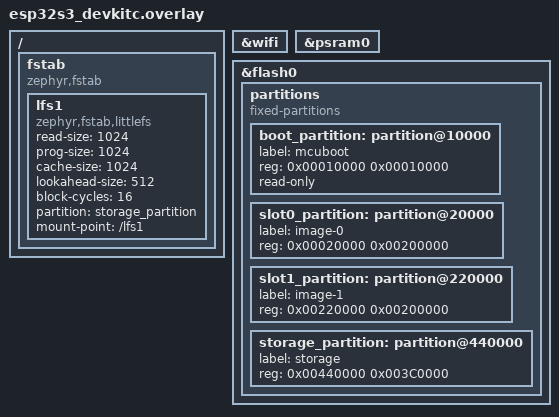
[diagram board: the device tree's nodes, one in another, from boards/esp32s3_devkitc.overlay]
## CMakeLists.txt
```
# SPDX-License-Identifier: Apache-2.0

cmake_minimum_required(VERSION 3.20.0)

find_package(Zephyr REQUIRED HINTS $ENV{ZEPHYR_BASE})
project(fs_shell)

set(MSS_DIR  "${CMAKE_CURRENT_SOURCE_DIR}/../../..")
set(MSS_SRC_DIR "${MSS_DIR}/src")
set(TRUSTCORE_LIB_DIR "${MSS_DIR}/bin_static")

include_directories(
  ${MSS_SRC_DIR}
)

FILE(GLOB app_sources src/*.c)
target_sources(app PRIVATE ${app_sources})

file(GLOB EXTERNAL_LIBS "${TRUSTCORE_LIB_DIR}/*.a")

if("${BOARD}" STREQUAL "native_sim")
  add_definitions("-D__DIGICERT_SAMPLE_NATIVE_SIM__")
elseif ("${BOARD}" STREQUAL "esp32s3_devkitc")
  add_definitions("-D__ENABLE_DIGICERT_ESP32S3__")
endif()

foreach(lib_path ${EXTERNAL_LIBS})
  get_filename_component(lib_name ${lib_path} NAME_WE)
  message(STATUS "Linking library: ${lib_name} => ${lib_path}")

  add_library(${lib_name} STATIC IMPORTED GLOBAL)
  set_target_properties(${lib_name} PROPERTIES IMPORTED_LOCATION ${lib_path})
  target_link_libraries(app PUBLIC ${lib_name})
endforeach()
```

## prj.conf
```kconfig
# Set the name of target binary
CONFIG_KERNEL_BIN_NAME="trustedge"
#CONFIG_DEBUG=y
#CONFIG_SIZE_OPTIMIZATIONS_AGGRESSIVE=y

# the number of bytes in the arena for C library malloc
CONFIG_COMMON_LIBC_MALLOC=y
CONFIG_COMMON_LIBC_MALLOC_ARENA_SIZE=110000

CONFIG_REQUIRES_FULL_LIBC=y

# number of bytes for k_malloc
CONFIG_HEAP_MEM_POOL_SIZE=25000

CONFIG_POSIX_API=y

# for enabling poxis threads
CONFIG_POSIX_THREADS=y # pthread
CONFIG_POSIX_TIMERS=y
CONFIG_THREAD_STACK_INFO=y
CONFIG_DYNAMIC_THREAD=y

CONFIG_DYNAMIC_THREAD_POOL_SIZE=20
CONFIG_DYNAMIC_THREAD_STACK_SIZE=2048
CONFIG_POSIX_THREAD_KEYS_MAX=20
CONFIG_POSIX_THREAD_THREADS_MAX=20
CONFIG_MAX_PTHREAD_MUTEX_COUNT=20
CONFIG_MAX_PTHREAD_COND_COUNT=20

# Enable thread awareness for debugging tools supporting it
CONFIG_DEBUG_THREAD_INFO=y

CONFIG_LOG=y

CONFIG_SHELL=y
CONFIG_SHELL_LOG_LEVEL_INF=y

CONFIG_FILE_SYSTEM=y
CONFIG_FILE_SYSTEM_SHELL=y

CONFIG_FILE_SYSTEM_LITTLEFS=y
CONFIG_FLASH_MAP=y
CONFIG_FLASH=y

# Networking config
CONFIG_NET_SOCKETS_LOG_LEVEL_DBG=n
CONFIG_NET_SOCKETS=y
CONFIG_NETWORKING=y
CONFIG_NET_IPV4=y
CONFIG_NET_IPV6=n
CONFIG_NET_IF_MAX_IPV4_COUNT=2
CONFIG_NET_TCP=y
CONFIG_NET_LOG=y

CONFIG_NET_SHELL=y

# Network address config
CONFIG_NET_CONFIG_SETTINGS=y
CONFIG_NET_CONFIG_NEED_IPV4=y
CONFIG_NET_DHCPV4=y

CONFIG_NET_TCP_LOG_LEVEL_DBG=n

CONFIG_HWINFO=y

CONFIG_MAIN_STACK_SIZE=4096

# Set current time from ntp server
CONFIG_SNTP=y
CONFIG_SNTP_LOG_LEVEL_DBG=n
CONFIG_NET_CONFIG_CLOCK_SNTP_INIT=y
CONFIG_NET_CONFIG_SNTP_INIT_RESYNC=y
CONFIG_NET_CONFIG_SNTP_INIT_SERVER="north-america.pool.ntp.org"
```

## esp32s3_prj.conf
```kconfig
# Set the name of target binary
#CONFIG_KERNEL_BIN_NAME="trustedge"
#CONFIG_DEBUG=y
#CONFIG_SIZE_OPTIMIZATIONS_AGGRESSIVE=y

# the number of bytes in the arena for C library malloc
#CONFIG_COMMON_LIBC_MALLOC=y
CONFIG_COMMON_LIBC_MALLOC_ARENA_SIZE=10000

CONFIG_HEAP_MEM_POOL_SIZE=50000
CONFIG_DYNAMIC_THREAD_STACK_SIZE=4096
CONFIG_MAIN_STACK_SIZE=4000

#CONFIG_ZTEST_STACK_SIZE=4096
CONFIG_SYSTEM_WORKQUEUE_STACK_SIZE=4096
CONFIG_LOG_PROCESS_THREAD_STACK_SIZE=8192
CONFIG_SHELL_STACK_SIZE=8192

CONFIG_LOG_BACKEND_FS=y
CONFIG_LOG_BACKEND_FS_FILE_SIZE=1024000
CONFIG_LOG_BACKEND_FS_FILES_LIMIT=5
CONFIG_LOG_BACKEND_FS_DIR="/lfs1/log"

CONFIG_PRINTK=y
CONFIG_LOG_CMDS=y
CONFIG_INIT_STACKS=y
CONFIG_KERNEL_SHELL=y
CONFIG_THREAD_MONITOR=y
CONFIG_BOOT_BANNER=n
CONFIG_THREAD_NAME=y
CONFIG_DEVICE_SHELL=y
CONFIG_DATE_SHELL=y
CONFIG_THREAD_RUNTIME_STATS=y
CONFIG_THREAD_RUNTIME_STATS_USE_TIMING_FUNCTIONS=y
CONFIG_STATS=y
CONFIG_STATS_SHELL=y
CONFIG_BOOTLOADER_MCUBOOT=y
CONFIG_NET_L2_WIFI_SHELL=y
CONFIG_SHELL=y
CONFIG_SHELL_BACKENDS=y
CONFIG_SHELL_BACKEND_SERIAL=y
CONFIG_FLASH_SHELL=y
CONFIG_CONSOLE=y
CONFIG_UART_CONSOLE=y
CONFIG_SERIAL=y
CONFIG_MULTITHREADING=y
CONFIG_PRINTK=y
CONFIG_LOG=y
CONFIG_LOG_BUFFER_SIZE=8192
CONFIG_ESP32_WIFI_STA_AUTO_DHCPV4=y
CONFIG_WIFI=y
CONFIG_WIFI_ESP32=y
CONFIG_NET_MAX_CONN=15

#CONFIG_NET_CONFIG_MY_IPV4_ADDR="192.168.1.142"
#CONFIG_NET_CONFIG_PEER_IPV4_ADDR="192.168.1.124"
#CONFIG_NET_CONFIG_MY_IPV4_GW="192.168.1.1"
#CONFIG_REQUIRES_FULL_LIBC=y

# number of bytes for k_malloc

#CONFIG_POSIX_API=y

# for enabling poxis threads
#CONFIG_POSIX_THREADS=y # pthread
#CONFIG_POSIX_TIMERS=y
#CONFIG_THREAD_STACK_INFO=y
#CONFIG_DYNAMIC_THREAD=y

#CONFIG_DYNAMIC_THREAD_POOL_SIZE=20
#CONFIG_POSIX_THREAD_KEYS_MAX=20
#CONFIG_POSIX_THREAD_THREADS_MAX=20
#CONFIG_MAX_PTHREAD_MUTEX_COUNT=20
#CONFIG_MAX_PTHREAD_COND_COUNT=20

# Enable thread awareness for debugging tools supporting it
#CONFIG_DEBUG_THREAD_INFO=y

#CONFIG_LOG=y

#CONFIG_SHELL=y
#CONFIG_SHELL_LOG_LEVEL_INF=y

#CONFIG_FILE_SYSTEM=y
#CONFIG_FILE_SYSTEM_SHELL=y

#CONFIG_FILE_SYSTEM_LITTLEFS=y
#CONFIG_FLASH_MAP=y
#CONFIG_FLASH=y

# Networking config
#CONFIG_NET_SOCKETS_LOG_LEVEL_DBG=n
#CONFIG_NET_SOCKETS=y
#CONFIG_NETWORKING=y
#CONFIG_NET_IPV4=y
#CONFIG_NET_DHCPV4=y
#CONFIG_NET_IPV6=n
#CONFIG_NET_IF_MAX_IPV4_COUNT=2
#CONFIG_NET_TCP=y
#CONFIG_NET_LOG=y

#CONFIG_NET_SHELL=y

#CONFIG_NET_CONFIG_SETTINGS=y
#CONFIG_NET_CONFIG_NEED_IPV4=y

#CONFIG_NET_MAX_CONN=10

#CONFIG_ZVFS_POLL_MAX=10
#CONFIG_ZVFS_OPEN_MAX=10
# Enable the DNS resolver
#CONFIG_DNS_RESOLVER=y
# Enable additional buffers
#CONFIG_DNS_RESOLVER_ADDITIONAL_BUF_CTR=5
# Enable additional queries
#CONFIG_DNS_RESOLVER_ADDITIONAL_QUERIES=2
# Enable mDNS support
#CONFIG_MDNS_RESOLVER=y
# Enable LLMNR support
#CONFIG_LLMNR_RESOLVER=n

#CONFIG_DNS_RESOLVER_MAX_SERVERS=2
#CONFIG_DNS_SERVER_IP_ADDRESSES=y
#CONFIG_DNS_NUM_CONCUR_QUERIES=5

#CONFIG_DNS_SERVER1="8.8.8.8:53"
#CONFIG_DNS_SERVER2="1.1.1.1:53"

#CONFIG_NET_PKT_RX_COUNT=12
#CONFIG_NET_PKT_TX_COUNT=12
#CONFIG_NET_BUF_RX_COUNT=64
#CONFIG_NET_BUF_TX_COUNT=64

#CONFIG_NET_TCP_LOG_LEVEL_DBG=n

#CONFIG_HWINFO=y


# Set current time from ntp server
#CONFIG_SNTP=y
#CONFIG_SNTP_LOG_LEVEL_DBG=n
#CONFIG_NET_CONFIG_CLOCK_SNTP_INIT=y
#CONFIG_NET_CONFIG_SNTP_INIT_RESYNC=y
#CONFIG_NET_CONFIG_SNTP_INIT_SERVER="north-america.pool.ntp.org"
```

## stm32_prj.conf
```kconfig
# Set the name of target binary
#CONFIG_KERNEL_BIN_NAME="trustedge"
#CONFIG_DEBUG=y
#CONFIG_SIZE_OPTIMIZATIONS_AGGRESSIVE=y

# the number of bytes in the arena for C library malloc
#CONFIG_COMMON_LIBC_MALLOC=y
CONFIG_COMMON_LIBC_MALLOC_ARENA_SIZE=102000

CONFIG_HEAP_MEM_POOL_SIZE=17000
CONFIG_DYNAMIC_THREAD_STACK_SIZE=14000
CONFIG_MAIN_STACK_SIZE=50000

#CONFIG_ZTEST_STACK_SIZE=4096
CONFIG_SYSTEM_WORKQUEUE_STACK_SIZE=4096
CONFIG_LOG_PROCESS_THREAD_STACK_SIZE=4096
CONFIG_SHELL_STACK_SIZE=4096

CONFIG_LOG_BACKEND_FS=y
CONFIG_LOG_BACKEND_FS_FILE_SIZE=1024000
CONFIG_LOG_BACKEND_FS_FILES_LIMIT=5
CONFIG_LOG_BACKEND_FS_DIR="/lfs1/log"

CONFIG_PRINTK=y
CONFIG_LOG_CMDS=y
CONFIG_INIT_STACKS=y
CONFIG_KERNEL_SHELL=y
CONFIG_THREAD_MONITOR=y
CONFIG_BOOT_BANNER=n
CONFIG_THREAD_NAME=y
CONFIG_DEVICE_SHELL=y
CONFIG_DATE_SHELL=y
CONFIG_THREAD_RUNTIME_STATS=y
CONFIG_THREAD_RUNTIME_STATS_USE_TIMING_FUNCTIONS=y
CONFIG_STATS=y
CONFIG_STATS_SHELL=y

#CONFIG_NET_CONFIG_MY_IPV4_ADDR="192.168.1.142"
#CONFIG_NET_CONFIG_PEER_IPV4_ADDR="192.168.1.124"
#CONFIG_NET_CONFIG_MY_IPV4_GW="192.168.1.1"
#CONFIG_REQUIRES_FULL_LIBC=y

# number of bytes for k_malloc

#CONFIG_POSIX_API=y

# for enabling poxis threads
#CONFIG_POSIX_THREADS=y # pthread
#CONFIG_POSIX_TIMERS=y
#CONFIG_THREAD_STACK_INFO=y
#CONFIG_DYNAMIC_THREAD=y

#CONFIG_DYNAMIC_THREAD_POOL_SIZE=20
#CONFIG_POSIX_THREAD_KEYS_MAX=20
#CONFIG_POSIX_THREAD_THREADS_MAX=20
#CONFIG_MAX_PTHREAD_MUTEX_COUNT=20
#CONFIG_MAX_PTHREAD_COND_COUNT=20

# Enable thread awareness for debugging tools supporting it
#CONFIG_DEBUG_THREAD_INFO=y

#CONFIG_LOG=y

#CONFIG_SHELL=y
#CONFIG_SHELL_LOG_LEVEL_INF=y

#CONFIG_FILE_SYSTEM=y
#CONFIG_FILE_SYSTEM_SHELL=y

#CONFIG_FILE_SYSTEM_LITTLEFS=y
#CONFIG_FLASH_MAP=y
#CONFIG_FLASH=y

# Networking config
#CONFIG_NET_SOCKETS_LOG_LEVEL_DBG=n
#CONFIG_NET_SOCKETS=y
#CONFIG_NETWORKING=y
#CONFIG_NET_IPV4=y
#CONFIG_NET_DHCPV4=y
#CONFIG_NET_IPV6=n
#CONFIG_NET_IF_MAX_IPV4_COUNT=2
#CONFIG_NET_TCP=y
#CONFIG_NET_LOG=y

#CONFIG_NET_SHELL=y

#CONFIG_NET_CONFIG_SETTINGS=y
#CONFIG_NET_CONFIG_NEED_IPV4=y

#CONFIG_NET_MAX_CONN=10

#CONFIG_ZVFS_POLL_MAX=10
#CONFIG_ZVFS_OPEN_MAX=10
# Enable the DNS resolver
#CONFIG_DNS_RESOLVER=y
# Enable additional buffers
#CONFIG_DNS_RESOLVER_ADDITIONAL_BUF_CTR=5
# Enable additional queries
#CONFIG_DNS_RESOLVER_ADDITIONAL_QUERIES=2
# Enable mDNS support
#CONFIG_MDNS_RESOLVER=y
# Enable LLMNR support
#CONFIG_LLMNR_RESOLVER=n

#CONFIG_DNS_RESOLVER_MAX_SERVERS=2
#CONFIG_DNS_SERVER_IP_ADDRESSES=y
#CONFIG_DNS_NUM_CONCUR_QUERIES=5

#CONFIG_DNS_SERVER1="8.8.8.8:53"
#CONFIG_DNS_SERVER2="1.1.1.1:53"

#CONFIG_NET_PKT_RX_COUNT=12
#CONFIG_NET_PKT_TX_COUNT=12
#CONFIG_NET_BUF_RX_COUNT=64
#CONFIG_NET_BUF_TX_COUNT=64

#CONFIG_NET_TCP_LOG_LEVEL_DBG=n

#CONFIG_HWINFO=y


# Set current time from ntp server
#CONFIG_SNTP=y
#CONFIG_SNTP_LOG_LEVEL_DBG=n
#CONFIG_NET_CONFIG_CLOCK_SNTP_INIT=y
#CONFIG_NET_CONFIG_SNTP_INIT_RESYNC=y
#CONFIG_NET_CONFIG_SNTP_INIT_SERVER="north-america.pool.ntp.org"
```

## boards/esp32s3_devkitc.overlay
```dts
/ {
    fstab {
        compatible = "zephyr,fstab";
        lfs1: lfs1 {
            compatible = "zephyr,fstab,littlefs";
            read-size = <1024>;
            prog-size = <1024>;
            cache-size = <1024>;
            lookahead-size = <512>;
            block-cycles = <16>;
            partition = <&storage_partition>;
            mount-point = "/lfs1";
        };
    };
};

&wifi {
    status = "okay";
};

&psram0 {
    status = "okay";
};

&flash0 {
    /delete-node/ partitions;
    partitions {
        compatible = "fixed-partitions";
        #address-cells = <1>;
        #size-cells = <1>;

        boot_partition: partition@10000 {
            label = "mcuboot";
            reg = <0x00010000 0x00010000>; /* 64KB */
            read-only;
        };

        slot0_partition: partition@20000 {
            label = "image-0";
            reg = <0x00020000 0x00200000>; /* 2MB */
        };

        slot1_partition: partition@220000 {
            label = "image-1";
            reg = <0x00220000 0x00200000>; /* 2MB */
        };

        storage_partition: partition@440000 {
            label = "storage";
            reg = <0x00440000 0x003C0000>; /* 3.75MB */
        };
    };
};
```

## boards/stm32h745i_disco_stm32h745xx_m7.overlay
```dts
/*
 * Copyright (c) 2023 S&C Electric Company <www.sandc.com>
 * Copyright (c) 2024 STMicroelectronics
 *
 * SPDX-License-Identifier: Apache-2.0
 */

/ {
	fstab {
		compatible = "zephyr,fstab";
		lfs1: lfs1 {
			compatible = "zephyr,fstab,littlefs";
			read-size = <32>;
			prog-size = <32>;
			cache-size = <256>;
			lookahead-size = <64>;
			block-cycles = <512>;
			partition = <&fs_partition>;
			mount-point = "/lfs1";
		};
	};
};
&flash0 {
	partitions {
		compatible = "fixed-partitions";
		#address-cells = <1>;
		#size-cells = <1>;

		boot_partition: partition@0 {
			label = "mcuboot";
			reg = <0x00000000 0x00010000>; /* 64k */
		};

		slot0_partition: partition@10000 {
			label = "image-0";
			reg = <0x00010000 0x0018DF30>;
		};

		/* total flash memory        -> 001FFC00 */
		/* remaining flash available -> 00061CD0 */
		/* use remaining flash for the file system */
		storage2_partition: partition@19DF30 {
			label = "storage2";
			reg = <0x0019DF30 0x00061CD0>;
		};
	};
};

&mt25ql512ab1 {
	partitions {
		fs_partition: partition@0 {
			label = "fs";
			reg = <0x0 DT_SIZE_M(64)>;
		};
	};
};
```

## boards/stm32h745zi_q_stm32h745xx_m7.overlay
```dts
/*
 * Copyright (c) 2023 S&C Electric Company <www.sandc.com>
 * Copyright (c) 2024 STMicroelectronics
 *
 * SPDX-License-Identifier: Apache-2.0
 */

/ {
	fstab {
		compatible = "zephyr,fstab";
		lfs1: lfs1 {
			compatible = "zephyr,fstab,littlefs";
			read-size = <32>;
			prog-size = <32>;
			cache-size = <256>;
			lookahead-size = <64>;
			block-cycles = <512>;
			partition = <&fs_partition>;
			mount-point = "/lfs1";
		};
	};
};
&flash0 {
	partitions {
		compatible = "fixed-partitions";
		#address-cells = <1>;
		#size-cells = <1>;

		boot_partition: partition@0 {
			label = "mcuboot";
			reg = <0x00000000 0x00010000>; /* 64k */
		};

		slot0_partition: partition@10000 {
			label = "image-0";
			reg = <0x00010000 0x0018DF30>;
		};

		/* total flash memory        -> 001FFC00 */
		/* remaining flash available -> 00061CD0 */
		/* use remaining flash for the file system */
		fs_partition: partition@19DF30 {
			label = "fs";
			reg = <0x0019DF30 0x00061CD0>;
		};
	};
};
```

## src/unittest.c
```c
/*
*  unittest.c
*
*   unit test support
*
* Copyright Mocana Corp 2006. All Rights Reserved.
* Proprietary and Confidential Material.
*
*/

#include "unittest.h"
#include "../src/common/mtypes.h"
    
#if (defined(WIN32) && defined(_DEBUG))
#include <CrtDbg.h>
#endif

#include <assert.h>
#if defined( __RTOS_WIN32__) || defined( __RTOS_LINUX__) || \
    defined(__RTOS_CYGWIN__) || defined( __RTOS_SOLARIS__) || \
    defined(__RTOS_VXWORKS__) || defined( __RTOS_OSX__) || \
    defined(__RTOS_OPENBSD__) || defined( __RTOS_FREEBSD__) || \
    defined(__RTOS_IRIX__) || defined( __RTOS_DUMMY__ ) || \
    defined(__RTOS_SYMBIAN32__)  || defined(__RTOS_WINCE__) || \
    defined(__RTOS_QNX__)
#include <stdio.h>
#define PRINTF      printf
#else
/* OSes with no printf go here and need to define equivalent functionality*/
/* need to support only %s and %d format strings with no extensions */
#endif
#define PRINTF      printf

/************************************
// Test execution debug-io support.
*************************************/
#define UT_DBG_COMM_HIGH_V   1 /* 0 = OFF 1 = ON */


/*-------------------------------------------------------------------------*/
#ifdef __UNITTEST_REMOTE_SUPPORT__


#define UT_DEBUG_PRINT(t,b,c) ut_debug_print(__FILE__, __LINE__, t, b, c)
static void ut_debug_print(const char* pfile, int iline, int printthis, char *str1, char *str2)
{
    char *pNull = "null";
    if (printthis == 0)
        return;
    if (!str1) str1 = pNull;
    if (!str2) str2 = pNull;
    printf("%s : %d : %s%s\n",pfile,iline,str1,str2);
    
}

#define MAX_DEBUGMSG_SIZE (4*1024)
char debugmsg_spot[MAX_DEBUGMSG_SIZE];
#endif /* __UNITTEST_REMOTE_SUPPORT__ */

int remote_target_socket = 0;	/* Needed by tests to determine if the peer IP address should be used of if localhost is acceptable */

int unittest_intEQ(const char* file, int line, const char* test, 
                int hint, int result, int expected)
{
#ifndef __UNITTEST_REMOTE_SUPPORT__

    if ( result != expected)
    {
        PRINTF("%s:%d:Test %s (%d) (%08x) result = %d, expected = %d\n", 
            file, line, test, hint, hint, result, expected);
        return 1;
    }
    return 0;
#else
    if ( result != expected)
    {
        sprintf(debugmsg_spot,"%s:%d:Test %s (%d) (%08x) result = %d, expected = %d\n",
            file, line, test, hint, hint, result, expected);
        unittest_write(debugmsg_spot);
        return 1;
    }
    return 0;
#endif
}


/*-------------------------------------------------------------------------*/

int unittest_intNE(const char* file, int line, const char* test, 
                int hint, int result, int unExpected)
{
#ifndef __UNITTEST_REMOTE_SUPPORT__
    if ( result == unExpected)
    {
        PRINTF("%s:%d:Test %s (%d)(%08x) result = %d, expected != %d\n",
            file, line, test, hint, hint, result, unExpected);
        return 1;
    }
    return 0;
#else
    if ( result == unExpected)
    {
        sprintf(debugmsg_spot,"%s:%d:Test %s (%d)(%08x) result = %d, expected != %d\n",
            file, line, test, hint, hint, result, unExpected);
        unittest_write(debugmsg_spot);
        return 1;
    }
    return 0;
#endif

}


/*-------------------------------------------------------------------------*/

int unittest_intGE( const char* file, int line, const char* testExpr, 
            int hint, int result, int expected)
{
#ifndef __UNITTEST_REMOTE_SUPPORT__
   if ( result < expected)
    {
        PRINTF("%s:%d:Test %s (%d)(%08x) result = %d, expected >= %d\n", 
            file, line, testExpr, hint, hint, result, expected);
        return 1;
    }
    return 0;
#else
    if ( result < expected)
     {
        sprintf(debugmsg_spot,"%s:%d:Test %s (%d)(%08x) result = %d, expected >= %d\n",
             file, line, testExpr, hint, hint, result, expected);
        unittest_write(debugmsg_spot);
         return 1;
     }
     return 0;
#endif
}


/*-------------------------------------------------------------------------*/

void unittest_write(const char* msg)
{
#ifndef __UNITTEST_REMOTE_SUPPORT__
    PRINTF("%s",msg);
#else
    if (remote_target_socket == 0)
    {
    	/* Host side. */
        PRINTF("%s",msg);
    }
    else
    {
    	/* Target side. */
        ut_write_output_cmd_tgt(remote_target_socket, msg);
    }
#endif
}


/*-------------------------------------------------------------------------*/

char* addhexChar( char* out, const unsigned char c)
{
    int n = (c >> 4) & 0x0F;
    *out++ = (char) ( (n < 0xA) ? '0' + n : 'A' + n - 0x0A);
    n = c & 0xF;
    *out++ =  (char) ( (n < 0xA) ? '0' + n : 'A' + n - 0x0A);
    return out;
}

/*-------------------------------------------------------------------------*/

void unittest_write_buffer( const unsigned char* buff, int buffLen)
{
    char line[82];
    line[80] = '\n';
    line[81] = 0;
    /* 6 groups of 8 hex + space = 54 +
       1 group of 24 chars = 24 -> 78 chars */

    while (buffLen)
    {
        char* out = line;
        int i, maxChars = ( buffLen > 24) ? 24 : buffLen;

        out = line;
        for (i = 0; i < maxChars; ++i)
        {
            out = addhexChar(out, buff[i]);
            if (i % 4 == 3)
            {
                *out++ = ' ';
            }
        }
        while (out != line +54)
        {
            *out++ = ' ';
        }

        for (i = 0; i < maxChars; ++i)
        {
            char c = buff[i];
            *out++ = (c >= 0x20 && c <= 0x7E) ? c : '.';
        }
        while (out != line + 80)
        {
            *out++ = ' ';
        }

        unittest_write(line);

        buff += maxChars;
        buffLen -= maxChars;
        
    }
}


/*-------------------------------------------------------------------------*/

int run_test( const char* testFunName, const char* fileName,
             TestFun testFun, int* pass)
{
    int retVal;

    
#if (defined(WIN32) && defined(_DEBUG))
    _CrtMemState memState;
    /* Get current flag */
    int tmpFlag = _CrtSetDbgFlag( _CRTDBG_REPORT_FLAG );
    /* Turn on extensive checks */
    tmpFlag |= (_CRTDBG_CHECK_ALWAYS_DF | _CRTDBG_LEAK_CHECK_DF);

    /* Set flag to the new value */
    _CrtSetDbgFlag( tmpFlag );
   _CrtSetReportMode( _CRT_WARN, _CRTDBG_MODE_DEBUG );
   _CrtSetReportMode( _CRT_ERROR, _CRTDBG_MODE_DEBUG );
   _CrtSetReportMode( _CRT_ASSERT, _CRTDBG_MODE_DEBUG );

   _CrtMemCheckpoint( &memState);

#endif
    
    PRINTF("Running test %s in file %s\n", testFunName, fileName);
#if 0 //ndef __RTOS_QNX__
    fflush(stdout);
#endif
    retVal = testFun();
#if (defined(WIN32) && defined(_DEBUG))
    if (!_CrtCheckMemory()) ++retVal;
    _CrtMemDumpAllObjectsSince(&memState);
#endif
    if ( 0==retVal)
    {
        PRINTF("%s: Pass\n\n", testFunName);
        ++(*pass);
    }
    else
    {
        PRINTF("%s: Fail: %d error(s)\n\n", testFunName, retVal);
    }
#if 0 //ndef __RTOS_QNX__
    fflush(stdout);
#endif

    return retVal;
}


/*-------------------------------------------------------------------------*/

void report( int total, int pass)
{
    PRINTF(  "\nPass:        %d", pass);
    PRINTF(  "\nFail:        %d", total - pass);
    PRINTF(  "\nTotal tests: %d\n", total);
}


/*-------------------------------------------------------------------------*/

int run_test_by_name( const char* name, TestDescriptor* tests, 
                      int num_tests, int* pass, int* total_tests)
{
    int retVal = 0;
    int i, j, name_len;
    const char* p;

    name_len = 0;
    p = name;

    while (*p) { ++name_len; ++p; }
    if (name_len)
    {
        for (i = 0; i < num_tests; ++i)
        {
            const char* testName;

            testName = tests[i].testName;

            for (j = 0; j < name_len; ++j)
            {
                if (testName[j] != name[j])
                {
                    break;
                }
            }
            if ( name_len == j) /* match */
            {
                (*total_tests)++;
                retVal += run_test(tests[i].testName, tests[i].fileName,
                                   tests[i].testFun, pass);
            }
        }
    }
    return retVal;
}


/*-------------------------------------------------------------------------*/

int list_test_names( TestDescriptor* tests, int num_tests)
{
    int i;

    PRINTF("Available tests:\n\n");
    for (i = 0; i < num_tests; ++i)
    {
        PRINTF("%s",tests[i].testName);
        PRINTF("\n");
    }

    return 0;
}


/*-------------------------------------------------------------------------*/

int run_test_by_names( const char* names[], int num_names, 
                       TestDescriptor* tests, int num_tests, 
                       int* pass, int* total_tests)
{
    int retVal = 0;
    int i;
    
    if (1 == num_names)
    {
        const char* option = names[0];

        if ('-' == option[0]  && 'h' == option[1]  && 0 == option[2] )
        {
            list_test_names(tests, num_tests);
            return 0;
        } 
    }

    for (i = 0; i < num_names; ++i)
    {
        retVal += run_test_by_name( names[i], tests, num_tests, pass, 
                                    total_tests);
    }
    return retVal;
}


#if 0
/* Disable until testmonkey infrastructure could be fixed to handle option
  flags
*/
#include "../src/common/moptions.h"
#include "../src/crypto/hw_accel.h"
#if defined(__ENABLE_HARDWARE_ACCEL_ASYNC_CRYPTO__)
static int utest_hwAccelCtx  = 0;
static int hwAccelRefCount = 0;

int
UNITTEST_getHwAccelChannel(void)
{
    if (0 == utest_hwAccelCtx) {
        HARDWARE_ACCEL_OPEN_CHANNEL(9, &utest_hwAccelCtx);
    }
exit:
    assert(utest_hwAccelCtx != 0);
    return utest_hwAccelCtx;
}

void
UNITTEST_releaseHwAccelChannel(int hwAccelCtx)
{
}
#endif
#endif

#ifdef __UNITTEST_REMOTE_SUPPORT__

/*********************************
 Real remote support.
************************************/
int connect_test_target_h(const char *tgtname, const char *execname,
						  int argc, char* argv[], int timeoutsecs, int *pconnfd)
{
	int rc = 0;
	UT_DEBUG_PRINT(UT_DBG_COMM_HIGH_V,"connect_test_target_h: target name=",tgtname);

    *pconnfd = 0;

    remote_target_socket = 0; /* Host side doesn't use one. */

	UT_DEBUG_PRINT(UT_DBG_COMM_HIGH_V,"connect_test_target_h: "," Load test target.");
	rc = ut_load_test_target_h(tgtname, execname, argc, argv, timeoutsecs);  /* May exec on localhost, may be a nop. */

	if (rc == 0)
	{
		UT_DEBUG_PRINT(UT_DBG_COMM_HIGH_V,"connect_test_target_h: "," Connect test target.");
		rc = ut_connect_test_target_h(tgtname, execname, argc, argv, timeoutsecs, pconnfd); /* Connect via socket. */
	}

	if (rc == 0)
	{
		UT_DEBUG_PRINT(UT_DBG_COMM_HIGH_V,"connect_test_target_h: "," Do Startup cmd.");
		rc = ut_startup_cmd_h(*pconnfd);
	}

	UT_DEBUG_PRINT(UT_DBG_COMM_HIGH_V,"connect_test_target_h"," done.");
	return rc;
}

int stop_test_target_h(int *pconnfd, int timeoutsecs)
{
	int rc = -1;
	UT_DEBUG_PRINT(UT_DBG_COMM_HIGH_V,"stop_test_target_h"," ...");
    if (*pconnfd != 0)
    {
    	UT_DEBUG_PRINT(UT_DBG_COMM_HIGH_V,"stop_test_target_h"," Sending shutdown cmd.");
    	rc = ut_shutdown_cmd_h(*pconnfd, timeoutsecs); /* Send Shutdown cmd and wait for ACK. */

    	rc = ut_disconnect_test_target_h(pconnfd); /* Closes socket. */
    }

	UT_DEBUG_PRINT(UT_DBG_COMM_HIGH_V,"stop_test_target_h"," done.");
	return rc;
}

int run_test_h( int connfd, const char* testFunName, const char* fileName,
             TestFun testFun, int* pass)
{
	int rc = -1;
	int retVal = 0;

	UT_DEBUG_PRINT(UT_DBG_COMM_HIGH_V,"run_test_h"," ...");
    if (connfd != 0)
    {
	    PRINTF("Remotely Running test %s in file %s\n", testFunName, fileName);
    	UT_DEBUG_PRINT(UT_DBG_COMM_HIGH_V,"run_test_h"," Sending run_test cmd.");
    	rc = ut_runtest_cmd_h(connfd, testFunName, fileName, &retVal); /* Send RUNTEST cmd, and wait until _FINISHED received.*/
    }

    if ((0==retVal) && (0==rc))
    {
        PRINTF("%s: Pass\n\n", testFunName);
        ++(*pass);
    }
    else
    {
    	if (rc != 0)
    	{
    		retVal = rc; /* This is to catch comm errors.*/
    	}
        PRINTF("%s: Fail: %d error(s)\n\n", testFunName, retVal);
    }

	UT_DEBUG_PRINT(UT_DBG_COMM_HIGH_V,"run_test_h"," done.");
  	return retVal;

}

int run_test_by_name_h( int connfd, const char* name, TestDescriptor* tests,
                      int num_tests, int* pass)
{
	int index = -1;
	int retVal = 0;
	UT_DEBUG_PRINT(UT_DBG_COMM_HIGH_V,"run_test_by_name_h"," ...");

	index = ut_testindexfromstr(tests, num_tests, name);
	if (index >= 0)
	{
		retVal += run_test_h(connfd, tests[index].testName, tests[index].fileName,
	                         tests[index].testFun, pass);
	}
	else
	{
        PRINTF("%s: Fail: Test not found.\n", name);
	}

	UT_DEBUG_PRINT(UT_DBG_COMM_HIGH_V,"run_test_by_name_h"," done.");
  	return 0;
}

int run_test_by_names_h( int connfd, const char* names[], int num_names,
                       TestDescriptor* tests,
                       int num_tests, int* pass)
{
    int retVal = 0;
    int i;

	UT_DEBUG_PRINT(UT_DBG_COMM_HIGH_V,"run_test_by_names_h"," ...");
    if (1 == num_names)
    {
        const char* option = names[0];

        if ('-' == option[0]  && 'h' == option[1]  && 0 == option[2] )
        {
            list_test_names(tests, num_tests);
            return 0;
        }
    }

    for (i = 0; i < num_names; ++i)
    {
        retVal += run_test_by_name_h(connfd, names[i], tests, num_tests, pass);
    }

	UT_DEBUG_PRINT(UT_DBG_COMM_HIGH_V,"run_test_by_names_h"," done.");
    return retVal;

}


int initcomm_tgt( struct sockaddr *phostip, int *pconnfd)
{
	int rc;

	UT_DEBUG_PRINT(UT_DBG_COMM_HIGH_V,"initcomm_tgt"," ...");
	UT_DEBUG_PRINT(UT_DBG_COMM_HIGH_V,"initcomm_tgt"," Accept incoming connect.");

	remote_target_socket = 0; /* Target side I/O needs this. But default to Zero... */

    rc = ut_initcomm_tgt(phostip, pconnfd);  /* Listen for incoming connections, and accept, returning connected socket. */
    if (rc == 0)
    {
    	remote_target_socket = *pconnfd; /* Target side I/O needs this.*/

    	UT_DEBUG_PRINT(UT_DBG_COMM_HIGH_V,"initcomm_tgt"," Wait for startup cmd.");
    	rc = ut_waitfor_startup_cmd_tgt(*pconnfd);
    }

	UT_DEBUG_PRINT(UT_DBG_COMM_HIGH_V,"initcomm_tgt"," done.");
	return rc;
}

int proc_runtest_cmds_tgt( struct sockaddr *phostip, int connfd, TestDescriptor* tests, int num_tests)
{
	int rc;
	UT_DEBUG_PRINT(UT_DBG_COMM_HIGH_V,"proc_runtest_cmds_tgt"," ...");
	UT_DEBUG_PRINT(UT_DBG_COMM_HIGH_V,"proc_runtest_cmds_tgt"," Wait for runtest cmds.");
	rc = ut_waitfor_runtest_cmd_tgt(connfd, tests, num_tests);
	UT_DEBUG_PRINT(UT_DBG_COMM_HIGH_V,"proc_runtest_cmds_tgt"," done.");
    return rc;
}

int stopcomm_tgt( int *pconnfd, int statusin)
{
	int rc;
	UT_DEBUG_PRINT(UT_DBG_COMM_HIGH_V,"stopcomm_tgt"," ...");

	rc = ut_stopcomm_tgt(pconnfd, statusin);

    remote_target_socket = 0; /* Target side I/O needs this. But default to Zero... */

	UT_DEBUG_PRINT(UT_DBG_COMM_HIGH_V,"stopcomm_tgt"," done.");
	return rc;
}

#endif  /*  __UNITTEST_REMOTE_SUPPORT__ */

#if defined(__ENABLE_DIGICERT_UNITTEST__)

#include <fcntl.h>
#include <unistd.h>
#include <string.h>
#include <stdio.h>

char *gpOutFile[256];
int gOutFD;
int stdoutFD;

void redirectOutput(char *pFile)
{
    fflush(NULL);
    memcpy(gpOutFile, pFile, strlen(pFile));
    gpOutFile[strlen(pFile)] = '\0';
    stdoutFD = dup(1);
    gOutFD = open(pFile, O_CREAT|O_WRONLY|O_TRUNC, 0666);
    dup2(gOutFD, 1);
}

void restoreOutput()
{
    fflush(NULL);
    dup2(stdoutFD, 1);
    close(stdoutFD);
}

#endif /* __ENABLE_DIGICERT_UNITTEST__ */
```

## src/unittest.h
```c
/*
*  unittest.h
*
*   unit test support
*
* Copyright Mocana Corp 2006. All Rights Reserved.
* Proprietary and Confidential Material.
*
*/


#ifndef __UNITTEST_HEADER__
#define __UNITTEST_HEADER__

#ifndef __MOC_LINE__
#define __MOC_LINE__ __LINE__
#endif

#if defined( __UNITTEST_REMOTE_SUPPORT__)
#if defined( __RTOS_WIN32__) || defined( __RTOS_LINUX__) || \
    defined(__RTOS_CYGWIN__) || defined( __RTOS_SOLARIS__) || \
    defined(__RTOS_VXWORKS__) || defined( __RTOS_OSX__) || \
    defined(__RTOS_OPENBSD__) || defined( __RTOS_FREEBSD__) || \
    defined(__RTOS_IRIX__) || defined( __RTOS_DUMMY__ ) || \
    defined(__RTOS_SYMBIAN32__)  || defined(__RTOS_WINCE__)
#include <sys/types.h>
#include <sys/socket.h>
#endif
#endif /* __UNITTEST_REMOTE_SUPPORT__ */

extern int remote_target_socket;    /* Needed by tests to determine if the peer IP address should be used of if localhost is acceptable */

/* prototypes */
typedef int (*TestFun)();

int unittest_intEQ(const char* file, int line, const char* testExpr, 
            int hint, int result, int expected);
int unittest_intGE( const char* file, int line, const char* testExpr, 
            int hint, int result, int expected);
int unittest_intNE( const char* file, int line, const char* testExpr, 
            int hint, int result, int expected);

int run_test( const char* testFunName, const char* fileName,
             TestFun testFun, int* pass);

void report( int total, int pass);

/* macros */
/* used by test programs */
#define UNITTEST_TRUE( h, t)     unittest_intNE(__FILE__, __LINE__, #t, (h), (t), 0)
#define UNITTEST_INT( h, t, v)   unittest_intEQ(__FILE__, __LINE__, #t, (h), (t), (v))
#define UNITTEST_STATUS( h, s)   unittest_intGE(__FILE__, __LINE__, #s, (h), (s), OK)
#define UNITTEST_VALIDPTR( h, p) unittest_intNE(__FILE__, __LINE__, #p, (h), (0!=p), 0)

/* UNITTEST_GOTO( TEST_MACRO, testret, exit_label) */
#define UNITTEST_GOTO( T, r, l)  if (T) { ++r; goto l; } 
#define UNITTEST_STATUS_GOTO( h, s, r, l) if (UNITTEST_STATUS(h,s)) { ++r; goto l; }

void unittest_write(const char* msg);

void unittest_write_buffer( const unsigned char* buff, int buffLen);

/* used by drivers */
typedef struct TestDescriptor
{
    int (*testFun)();
    char* testName;
    char* fileName;
} TestDescriptor;

#define TEST_DESC(f, a) { (a), #a, (f) }

int run_test_by_name( const char* name, TestDescriptor* tests, 
                      int num_tests, int* pass, int* total_tests);

int run_test_by_names( const char* names[], int num_names, 
                       TestDescriptor* tests, 
                       int num_tests, int* pass, int* total_tests);

#define RUN_TEST_BY_NAME( n, t, nt, p) run_test_by_name( (n), (t), (nt), (p))
#define RUN_TEST_BY_NAMES( n, nn, t, nt, p, tt) run_test_by_names( (n), (nn), (t), (nt), (p), (tt))
#define RUN_TEST( f, t, p) run_test( #t, (f), (t), (p))

#ifndef __UNITTEST_REMOTE_SUPPORT__
/* baby steps. Define the _H macros to just call the above, or "return" a 0. */
#define CONNECT_TEST_TARGET_H(in,en,ac,av,tm,cf) 0
#define RUN_TEST_BY_NAME_H( c, n, t, nt, p) RUN_TEST_BY_NAME( (n), (t), (nt), (p))
#define RUN_TEST_BY_NAMES_H( c, n, nn, t, nt, p, tt) RUN_TEST_BY_NAMES( (n), (nn), (t), (nt), (p), (tt))
#define RUN_TEST_H( c, f, t, p) RUN_TEST( (f), (t), (p))
#define STOP_TEST_TARGET_H(cf,tm) 0
#define INITCOMM_TGT(hi, cf) 0
#define PROC_RUNTEST_CMDS_TGT(hi, cf, td, nt) 0
#define STOPCOMM_TGT(cf, st) 0
#else
int connect_test_target_h(const char *tgtname, const char *execname,
						  int argc, char* argv[], int timeoutsecs, int *pconnfd);

int stop_test_target_h(int *pconnfd, int timeoutsecs);

int run_test_h( int connfd, const char* testFunName, const char* fileName,
             TestFun testFun, int* pass);

int run_test_by_name_h( int connfd, const char* name, TestDescriptor* tests,
                      int num_tests, int* pass);

int run_test_by_names_h( int connfd, const char* names[], int num_names,
                       TestDescriptor* tests,
                       int num_tests, int* pass);

int initcomm_tgt( struct sockaddr *phostip, int *pconnfd);
int proc_runtest_cmds_tgt( struct sockaddr *phostip, int connfd, TestDescriptor* tests, int num_tests);
int stopcomm_tgt( int *pconnfd, int statusin);

// Real macros used for remote test execution.
// Host side
#define CONNECT_TEST_TARGET_H(in,en,ac,av,tm,cf) connect_test_target_h( (in), (en), (ac), (av), (tm), (cf))
#define RUN_TEST_BY_NAME_H( c, n, t, nt, p) run_test_by_name_h( (c), (n), (t), (nt), (p))
#define RUN_TEST_BY_NAMES_H( c, n, nn, t, nt, p, tt) run_test_by_names_h( (c), (n), (nn), (t), (nt), (p))
#define RUN_TEST_H( c, f, t, p) run_test_h( (c), #t, (f), (t), (p))
#define STOP_TEST_TARGET_H(cf,tm) stop_test_target_h((cf), (tm))
// Target side
#define INITCOMM_TGT(hi, cf) initcomm_tgt( (hi), (cf))
#define PROC_RUNTEST_CMDS_TGT(hi, cf, td, nt) proc_runtest_cmds_tgt( (hi), (cf), (td), (nt))
#define STOPCOMM_TGT(cf, st) stopcomm_tgt((cf), (st))
#endif

#if defined(__ENABLE_HARDWARE_ACCEL_SYNC_CRYPTO__) || defined(__ENABLE_HARDWARE_ACCEL_ASYNC_CRYPTO__)
#define HW_ACCEL_GET_CONTEXT(sb)        \
        sbyte4 sb = UNITTEST_getHwAccelChannel()
#define HW_ACCEL_FREE_CONTEXT(sb)       \
        UNITTEST_releaseHwAccelChannel(sb)
#else                  /* __ENABLE_DIGICERT_HARDWARE_CRYPTO_ACCEL__ */
#define HW_ACCEL_GET_CONTEXT(sb)
#define HW_ACCEL_FREE_CONTEXT(sb)
#endif                  /* __ENABLE_DIGICERT_HARDWARE_CRYPTO_ACCEL__ */


/* FILE_PATH macro for windows CE that does not 
have the concept of "current directory" */
#ifndef FILE_PATH
#ifdef TEST_DIR
#define xstr(m) str(m)
#define str(m)  #m
#define FILE_PATH(a)  xstr(TEST_DIR) a
#else
#define FILE_PATH(a) a
#endif
#endif

void redirectOutput(char *pFile);
void restoreOutput();
#define REDIRECT_OUTPUT(_file)  redirectOutput((char *) _file);
#define RESTORE_OUTPUT          restoreOutput();

#endif
```

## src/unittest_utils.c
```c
/*
 * unittest_utils.c
 *
 * functions useful for writing tests
 *
 * Copyright Mocana Corp 2009. All Rights Reserved.
 * Proprietary and Confidential Material.
 *
 */


#ifndef __RTOS_ZEPHYR__
#define __RTOS_LINUX__
#define __RTOS_ZEPHYR__
#endif

#include "common/moptions.h"
#include "common/mtypes.h"
#include "common/mocana.h"
#include "crypto/hw_accel.h"

#include "common/mdefs.h"
#include "common/merrors.h"
#include "common/mstdlib.h"
#include "common/mrtos.h"
#include "unittest_utils.h"


/*---------------------------------------------------------------------------*/

static ubyte UNITTEST_UTILS_ValOfHexChar( sbyte c)
{
    if ('0' <= c && c <= '9')
    {
        return (ubyte) (c - '0');
    }
    else if ( 'A' <= c && c <= 'F')
    {
        return (ubyte) ( c + 10 - 'A');
    }
    else if ( 'a' <= c && c <= 'f')
    {
        return (ubyte) ( c + 10 - 'a');
    }
    return 0; /* ??? */
}


/*---------------------------------------------------------------------------*/

ubyte4 UNITTEST_UTILS_str_to_byteStr( const sbyte* s, ubyte** bs)
{
    ubyte* buffer = 0;
    ubyte4 bsLen;
    ubyte4 sLen = DIGI_STRLEN( s);
    ubyte* pTemp;

    bsLen = (sLen+1)/2;
    buffer = MALLOC( bsLen + 1); /* to prevent a malloc 0 */
    if (!buffer)
    {
        *bs = 0;
        return 0;
    }

    pTemp = buffer;

    if ( sLen & 1)
    {
        *pTemp++ = UNITTEST_UTILS_ValOfHexChar(*s++);
    }
    while ( *s)
    {
        *pTemp = (ubyte) ((UNITTEST_UTILS_ValOfHexChar(*s++)) << 4);
        *pTemp++ |= (UNITTEST_UTILS_ValOfHexChar(*s++));
    }
    *bs = buffer;
    return bsLen;
}


/*-----------------------------------------------------------------*/

void
UNITTEST_UTILS_make_file_name( const sbyte* root, const TimeDate* td, sbyte buffer[])
{
    ubyte4 len;

    len = DIGI_STRLEN( root);
    DIGI_MEMCPY( buffer, root, len);
    buffer += len;
    *buffer++ = '_';

    DIGI_UTOA( td->m_year + 1970, (ubyte*) buffer, &len);
    buffer += len;
    *buffer++ = '_';

    DIGI_UTOA( td->m_month, (ubyte*) buffer, &len);
    buffer += len;
    *buffer++ = '_';

    DIGI_UTOA( td->m_day, (ubyte*) buffer, &len);
    buffer += len;
    *buffer++ = '_';

    DIGI_UTOA( td->m_hour, (ubyte*) buffer, &len);
    buffer += len;
    *buffer++ = '_';

    DIGI_UTOA( td->m_minute, (ubyte*) buffer, &len);
    buffer += len;
    *buffer++ = '_';

    DIGI_UTOA( td->m_second, (ubyte*) buffer, &len);
    buffer += len;
    *buffer++ = 0;
}
```

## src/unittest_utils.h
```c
/*
 * unittest_utils.h
 *
 * functions useful for writing tests
 *
 * Copyright Mocana Corp 2009. All Rights Reserved.
 * Proprietary and Confidential Material.
 *
 */

#ifndef __UNITTEST_UTILS__
#define __UNITTEST_UTILS__

ubyte4 UNITTEST_UTILS_str_to_byteStr( const sbyte* s, ubyte** bs);
void UNITTEST_UTILS_make_file_name( const sbyte* root, const TimeDate* td, sbyte buffer[]);


#endif
```
